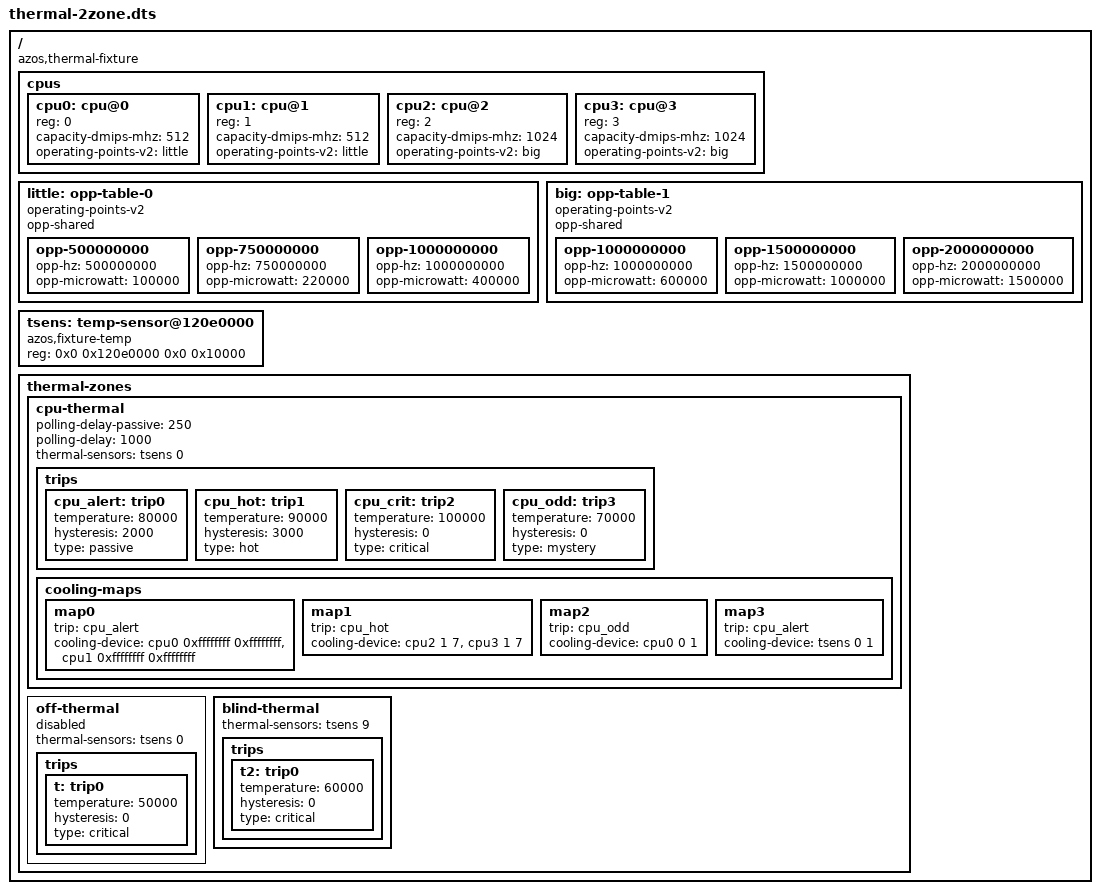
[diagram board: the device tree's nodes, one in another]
// SPDX-License-Identifier: Apache-2.0 OR GPL-2.0-only
// SPDX-FileCopyrightText: 2026 Fernando Rodriguez
// Thermal framework host fixture: two clusters (cpu0-1 little, cpu2-3 big), a
// cpu-thermal zone with passive, hot, critical and one unknown-type trip and
// four cooling maps (two with two CPUs of one domain, one with explicit
// states, one naming an unknown trip, one naming an unknown CPU), a disabled
// zone and a zone whose sensor the board does not know. Invented numbers.
// Rebuild: dtc -I dts -O dtb -o thermal-2zone.dtb thermal-2zone.dts
/dts-v1/;
/ {
	#address-cells = <2>;
	#size-cells = <2>;
	compatible = "azos,thermal-fixture";
	cpus {
		#address-cells = <1>;
		#size-cells = <0>;
		cpu0: cpu@0 { device_type = "cpu"; reg = <0>; capacity-dmips-mhz = <512>;
			operating-points-v2 = <&little>; #cooling-cells = <2>; };
		cpu1: cpu@1 { device_type = "cpu"; reg = <1>; capacity-dmips-mhz = <512>;
			operating-points-v2 = <&little>; #cooling-cells = <2>; };
		cpu2: cpu@2 { device_type = "cpu"; reg = <2>; capacity-dmips-mhz = <1024>;
			operating-points-v2 = <&big>; #cooling-cells = <2>; };
		cpu3: cpu@3 { device_type = "cpu"; reg = <3>; capacity-dmips-mhz = <1024>;
			operating-points-v2 = <&big>; #cooling-cells = <2>; };
	};
	little: opp-table-0 {
		compatible = "operating-points-v2";
		opp-shared;
		opp-500000000 { opp-hz = /bits/ 64 <500000000>; opp-microwatt = <100000>; };
		opp-750000000 { opp-hz = /bits/ 64 <750000000>; opp-microwatt = <220000>; };
		opp-1000000000 { opp-hz = /bits/ 64 <1000000000>; opp-microwatt = <400000>; };
	};
	big: opp-table-1 {
		compatible = "operating-points-v2";
		opp-shared;
		opp-1000000000 { opp-hz = /bits/ 64 <1000000000>; opp-microwatt = <600000>; };
		opp-1500000000 { opp-hz = /bits/ 64 <1500000000>; opp-microwatt = <1000000>; };
		opp-2000000000 { opp-hz = /bits/ 64 <2000000000>; opp-microwatt = <1500000>; };
	};
	tsens: temp-sensor@120e0000 {
		compatible = "azos,fixture-temp";
		reg = <0x0 0x120e0000 0x0 0x10000>;
		#thermal-sensor-cells = <1>;
		#cooling-cells = <2>;
	};
	thermal-zones {
		cpu-thermal {
			polling-delay-passive = <250>;
			polling-delay = <1000>;
			thermal-sensors = <&tsens 0>;
			trips {
				cpu_alert: trip0 {
					temperature = <80000>;
					hysteresis = <2000>;
					type = "passive";
				};
				cpu_hot: trip1 {
					temperature = <90000>;
					hysteresis = <3000>;
					type = "hot";
				};
				cpu_crit: trip2 {
					temperature = <100000>;
					hysteresis = <0>;
					type = "critical";
				};
				cpu_odd: trip3 {
					temperature = <70000>;
					hysteresis = <0>;
					type = "mystery";
				};
			};
			cooling-maps {
				map0 {
					trip = <&cpu_alert>;
					cooling-device = <&cpu0 0xffffffff 0xffffffff>, <&cpu1 0xffffffff 0xffffffff>;
				};
				map1 {
					trip = <&cpu_hot>;
					cooling-device = <&cpu2 1 7>, <&cpu3 1 7>;
				};
				map2 {
					trip = <&cpu_odd>;
					cooling-device = <&cpu0 0 1>;
				};
				map3 {
					trip = <&cpu_alert>;
					cooling-device = <&tsens 0 1>;
				};
			};
		};
		off-thermal {
			status = "disabled";
			thermal-sensors = <&tsens 0>;
			trips { t: trip0 { temperature = <50000>; hysteresis = <0>; type = "critical"; }; };
		};
		blind-thermal {
			thermal-sensors = <&tsens 9>;
			trips { t2: trip0 { temperature = <60000>; hysteresis = <0>; type = "critical"; }; };
		};
	};
};
